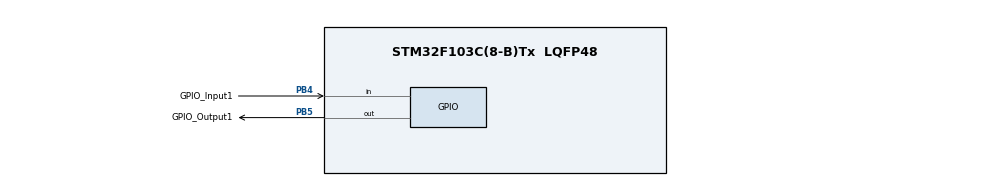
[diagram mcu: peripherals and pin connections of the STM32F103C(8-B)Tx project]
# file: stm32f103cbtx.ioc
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Mcu.Family=STM32F1
Mcu.Name=STM32F103C(8-B)Tx
Mcu.Package=LQFP48
NVIC.PriorityGroup=NVIC_PRIORITYGROUP_4
PA13.Mode=Serial_Wire
PA13.Signal=SYS_JTMS-SWDIO
PA14.Mode=Serial_Wire
PA14.Signal=SYS_JTCK-SWCLK
PB4.GPIO_Label=GPIO_Input1
PB4.GPIO_PuPd=GPIO_PULLUP
PB4.Signal=GPIO_Input
PB5.GPIO_Label=GPIO_Output1
PB5.GPIO_ModeDefaultOutputPP=GPIO_MODE_OUTPUT_PP
PB5.GPIO_PuPd=GPIO_PULLDOWN
PB5.GPIO_Speed=GPIO_SPEED_FREQ_LOW
PB5.Signal=GPIO_Output
PD0-OSC_IN.Mode=HSE-External-Oscillator
PD0-OSC_IN.Signal=RCC_OSC_IN
PD1-OSC_OUT.Mode=HSE-External-Oscillator
PD1-OSC_OUT.Signal=RCC_OSC_OUT
ProjectManager.HeapSize=0x200
ProjectManager.StackSize=0x400
ProjectManager.TargetToolchain=MDK-ARM V5.32
RCC.AHBFreq_Value=72000000
RCC.APB1CLKDivider=RCC_HCLK_DIV2
RCC.APB1Freq_Value=36000000
RCC.APB1TimFreq_Value=72000000
RCC.APB2Freq_Value=72000000
RCC.APB2TimFreq_Value=72000000
RCC.HCLKFreq_Value=72000000
RCC.PLLMUL=RCC_PLL_MUL9
RCC.PLLSourceVirtual=RCC_PLLSOURCE_HSE
RCC.SYSCLKFreq_VALUE=72000000
RCC.SYSCLKSource=RCC_SYSCLKSOURCE_PLLCLK
RCC.USBFreq_Value=72000000
board=custom

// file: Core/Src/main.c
/* USER CODE BEGIN Header */
/**
  ******************************************************************************
  * @file           : main.c
  * @brief          : Main program body
  ******************************************************************************
  * @attention
  *
  * Copyright (c) 2025 STMicroelectronics.
  * All rights reserved.
  *
  * This software is licensed under terms that can be found in the LICENSE file
  * in the root directory of this software component.
  * If no LICENSE file comes with this software, it is provided AS-IS.
  *
  ******************************************************************************
  */
/* USER CODE END Header */
#include "main.h"
#include "gpio.h"

/* USER CODE BEGIN PM */
uint32_t cnt = 0;
/* USER CODE END PM */

void SystemClock_Config(void);

/* USER CODE BEGIN 0 */
__STATIC_INLINE void Enable_Peripherals_Clock(void) {
    SET_BIT(RCC->APB2ENR, 1UL << 0UL);  // 启动AFIO时钟
    SET_BIT(RCC->APB1ENR, 1UL << 28UL); // 启动PWR时钟
    SET_BIT(RCC->APB2ENR, 1UL << 5UL);  // 启动GPIOD时钟
    SET_BIT(RCC->APB2ENR, 1UL << 2UL);  // 启动GPIOA时钟
    SET_BIT(RCC->APB2ENR, 1UL << 3UL);  // 启动GPIOB时钟
    __NOP(); // 稍微延时一下下
}

__STATIC_INLINE void GPIO_Configure(void) {
    /* PB4 */
    MODIFY_REG(GPIOB->CRL, 0x0F << 16UL, 0x08 << 16UL); // PB4输入模式
    SET_BIT(GPIOB->ODR, 0X01 << 4UL); // PB4设置上拉

    /* PB5 */
    // 寄存器方式
    //SET_BIT(GPIOB->BRR, 0X01 << 5UL); // PB5复位（下拉）、学习LL库，设置GPIO输出模式之前，先复位
    //MODIFY_REG(GPIOB->CRL, 0x0F << 20UL, 0x02 << 20UL); // PB5输出推挽模式
    // LL库的另一种方式
    LL_GPIO_ResetOutputPin(GPIOB, LL_GPIO_PIN_5);                  // PB5复位
    LL_GPIO_SetPinMode(GPIOB, LL_GPIO_PIN_5, LL_GPIO_MODE_OUTPUT); // PB5输出模式
    LL_GPIO_SetPinOutputType(GPIOB, LL_GPIO_PIN_5, LL_GPIO_OUTPUT_PUSHPULL); // 推挽输出

}
/* USER CODE END 0 */

int main(void)
{
  /* USER CODE BEGIN 1 */
  Enable_Peripherals_Clock(); // 启动所需外设的时钟
  /* USER CODE END 1 */

  /* MCU Configuration--------------------------------------------------------*/

  /* Reset of all peripherals, Initializes the Flash interface and the Systick. */
  //LL_APB2_GRP1_EnableClock(LL_APB2_GRP1_PERIPH_AFIO);
  //LL_APB1_GRP1_EnableClock(LL_APB1_GRP1_PERIPH_PWR);

  /* System interrupt init*/
  NVIC_SetPriorityGrouping(NVIC_PRIORITYGROUP_4);

  /* SysTick_IRQn interrupt configuration */
  NVIC_SetPriority(SysTick_IRQn, NVIC_EncodePriority(NVIC_GetPriorityGrouping(),15, 0));

  /** NOJTAG: JTAG-DP Disabled and SW-DP Enabled
  */
  LL_GPIO_AF_Remap_SWJ_NOJTAG();

  /* Configure the system clock */
  SystemClock_Config();

  /* USER CODE BEGIN SysInit */
  SysTick->CTRL |= 0x01UL << 1UL; // 开启SysTick中断
  /* USER CODE END SysInit */

  /* Initialize all configured peripherals */
  //MX_GPIO_Init();
  /* USER CODE BEGIN 2 */
  GPIO_Configure();
  /* USER CODE END 2 */

  /* Infinite loop */
  while (1)
  {
    SET_BIT(GPIOB->BSRR, 1 << 5UL); // PB5电平拉高
    LL_mDelay(1000); // 延迟1S
    SET_BIT(GPIOB->BSRR, 1 << (5UL + 16UL)); // PB5电平拉低
    LL_mDelay(1000); // 延迟1S
  }
}

void SystemClock_Config(void)
{
  LL_FLASH_SetLatency(LL_FLASH_LATENCY_2);
  while(LL_FLASH_GetLatency()!= LL_FLASH_LATENCY_2)
  {
  }
  LL_RCC_HSE_Enable();

   /* Wait till HSE is ready */
  while(LL_RCC_HSE_IsReady() != 1)
  {

  }
  LL_RCC_PLL_ConfigDomain_SYS(LL_RCC_PLLSOURCE_HSE_DIV_1, LL_RCC_PLL_MUL_9);
  LL_RCC_PLL_Enable();

   /* Wait till PLL is ready */
  while(LL_RCC_PLL_IsReady() != 1)
  {

  }
  LL_RCC_SetAHBPrescaler(LL_RCC_SYSCLK_DIV_1);
  LL_RCC_SetAPB1Prescaler(LL_RCC_APB1_DIV_2);
  LL_RCC_SetAPB2Prescaler(LL_RCC_APB2_DIV_1);
  LL_RCC_SetSysClkSource(LL_RCC_SYS_CLKSOURCE_PLL);

   /* Wait till System clock is ready */
  while(LL_RCC_GetSysClkSource() != LL_RCC_SYS_CLKSOURCE_STATUS_PLL)
  {

  }
  LL_Init1msTick(72000000);
  LL_SetSystemCoreClock(72000000);
}

void Error_Handler(void)
{
  __disable_irq();
  while (1)
  {
  }
}
